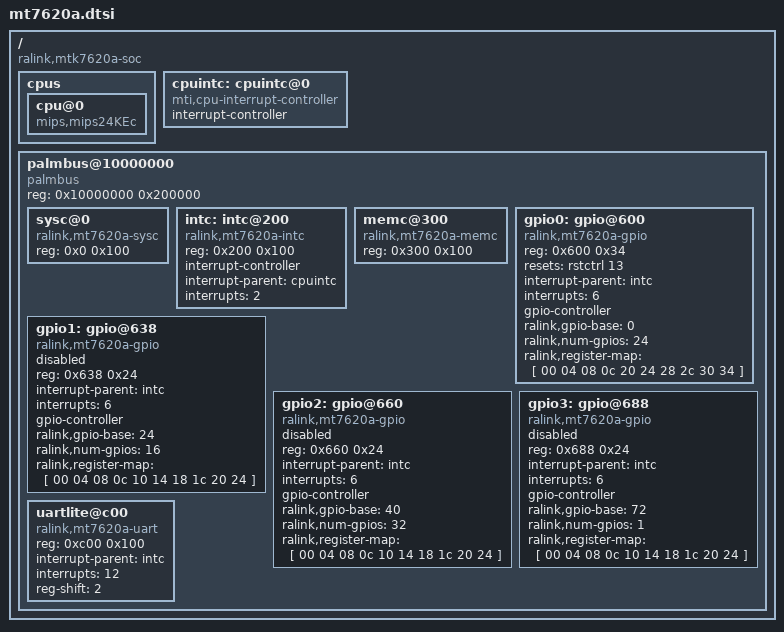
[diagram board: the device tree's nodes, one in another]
/ {
	#address-cells = <1>;
	#size-cells = <1>;
	compatible = "ralink,mtk7620a-soc";

	cpus {
		cpu@0 {
			compatible = "mips,mips24KEc";
		};
	};

	cpuintc: cpuintc@0 {
		#address-cells = <0>;
		#interrupt-cells = <1>;
		interrupt-controller;
		compatible = "mti,cpu-interrupt-controller";
	};

	palmbus@10000000 {
		compatible = "palmbus";
		reg = <0x10000000 0x200000>;
                ranges = <0x0 0x10000000 0x1FFFFF>;

		#address-cells = <1>;
		#size-cells = <1>;

		sysc@0 {
			compatible = "ralink,mt7620a-sysc";
			reg = <0x0 0x100>;
		};

		intc: intc@200 {
			compatible = "ralink,mt7620a-intc", "ralink,rt2880-intc";
			reg = <0x200 0x100>;

			interrupt-controller;
			#interrupt-cells = <1>;

			interrupt-parent = <&cpuintc>;
			interrupts = <2>;
		};

		memc@300 {
			compatible = "ralink,mt7620a-memc", "ralink,rt3050-memc";
			reg = <0x300 0x100>;
		};
		gpio0: gpio@600 {
			compatible = "ralink,mt7620a-gpio", "ralink,rt2880-gpio";
//gpio0-gpio3共4组gpio:ralink,rt2880-gpio字段与drivers/gpio/gpio-ralink.c匹配.
			reg = <0x600 0x34>;

			resets = <&rstctrl 13>;
			reset-names = "pio";

			interrupt-parent = <&intc>;
			interrupts = <6>;

			gpio-controller;
			#gpio-cells = <2>;

			ralink,gpio-base = <0>;
			ralink,num-gpios = <24>;
			ralink,register-map = [ 00 04 08 0c
						20 24 28 2c
						30 34 ];
		};

		gpio1: gpio@638 {
			compatible = "ralink,mt7620a-gpio", "ralink,rt2880-gpio";
			reg = <0x638 0x24>;

			interrupt-parent = <&intc>;
			interrupts = <6>;

			gpio-controller;
			#gpio-cells = <2>;

			ralink,gpio-base = <24>;
			ralink,num-gpios = <16>;
			ralink,register-map = [ 00 04 08 0c
						10 14 18 1c
						20 24 ];

			status = "disabled";
		};

		gpio2: gpio@660 {
			compatible = "ralink,mt7620a-gpio", "ralink,rt2880-gpio";
			reg = <0x660 0x24>;

			interrupt-parent = <&intc>;
			interrupts = <6>;

			gpio-controller;
			#gpio-cells = <2>;

			ralink,gpio-base = <40>;
			ralink,num-gpios = <32>;
			ralink,register-map = [ 00 04 08 0c
						10 14 18 1c
						20 24 ];

			status = "disabled";
		};

		gpio3: gpio@688 {
			compatible = "ralink,mt7620a-gpio", "ralink,rt2880-gpio";
			reg = <0x688 0x24>;

			interrupt-parent = <&intc>;
			interrupts = <6>;

			gpio-controller;
			#gpio-cells = <2>;

			ralink,gpio-base = <72>;
			ralink,num-gpios = <1>;
			ralink,register-map = [ 00 04 08 0c
						10 14 18 1c
						20 24 ];

			status = "disabled";
		};

		uartlite@c00 {
			compatible = "ralink,mt7620a-uart", "ralink,rt2880-uart", "ns16550a";
			reg = <0xc00 0x100>;

			interrupt-parent = <&intc>;
			interrupts = <12>;

			reg-shift = <2>;
		};
	};
};
